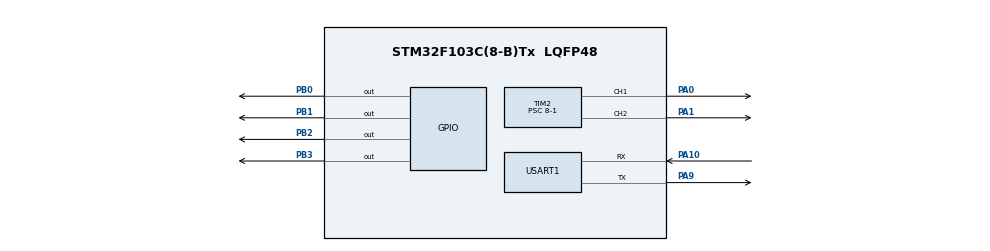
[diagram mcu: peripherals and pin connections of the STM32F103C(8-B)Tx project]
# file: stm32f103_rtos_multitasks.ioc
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FREERTOS.Tasks01=motor01,24,128,StartMotor01,Default,NULL,Dynamic,NULL,NULL;motor02,8,128,StartMotor02,Default,NULL,Dynamic,NULL,NULL
FREERTOS.configUSE_NEWLIB_REENTRANT=1
Mcu.Family=STM32F1
Mcu.Name=STM32F103C(8-B)Tx
Mcu.Package=LQFP48
NVIC.PriorityGroup=NVIC_PRIORITYGROUP_4
NVIC.TIM1_UP_IRQn=true\:15\:0\:false\:false\:true\:false\:false\:true\:true
NVIC.TimeBase=TIM1_UP_IRQn
NVIC.TimeBaseIP=TIM1
PA0-WKUP.Signal=S_TIM2_CH1_ETR
PA1.Signal=S_TIM2_CH2
PA10.Mode=Asynchronous
PA10.Signal=USART1_RX
PA13.Mode=Serial_Wire
PA13.Signal=SYS_JTMS-SWDIO
PA14.Mode=Serial_Wire
PA14.Signal=SYS_JTCK-SWCLK
PA9.Mode=Asynchronous
PA9.Signal=USART1_TX
PB0.Signal=GPIO_Output
PB1.Signal=GPIO_Output
PB2.Signal=GPIO_Output
PB3.Signal=GPIO_Output
ProjectManager.HeapSize=0x200
ProjectManager.StackSize=0x400
ProjectManager.TargetToolchain=STM32CubeIDE
RCC.APB1Freq_Value=8000000
RCC.APB2Freq_Value=8000000
SH.S_TIM2_CH1_ETR.0=TIM2_CH1,PWM Generation1 CH1
SH.S_TIM2_CH2.0=TIM2_CH2,PWM Generation2 CH2
TIM2.Channel-PWM\ Generation1\ CH1=TIM_CHANNEL_1
TIM2.Channel-PWM\ Generation2\ CH2=TIM_CHANNEL_2
TIM2.Period=1000-1
TIM2.Prescaler=8-1
USART1.VirtualMode=VM_ASYNC
VP_FREERTOS_VS_CMSIS_V2.Mode=CMSIS_V2
VP_SYS_VS_tim1.Mode=TIM1
board=custom

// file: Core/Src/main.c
/* USER CODE BEGIN Header */
/**
  ******************************************************************************
  * @file           : main.c
  * @brief          : Main program body
  ******************************************************************************
  * @attention
  *
  * Copyright (c) 2023 STMicroelectronics.
  * All rights reserved.
  *
  * This software is licensed under terms that can be found in the LICENSE file
  * in the root directory of this software component.
  * If no LICENSE file comes with this software, it is provided AS-IS.
  *
  ******************************************************************************
  */
/* USER CODE END Header */
#include "main.h"
#include "cmsis_os.h"

TIM_HandleTypeDef htim2;

UART_HandleTypeDef huart1;

/* Definitions for motor01 */
osThreadId_t motor01Handle;
const osThreadAttr_t motor01_attributes = {
  .name = "motor01",
  .stack_size = 128 * 4,
  .priority = (osPriority_t) osPriorityNormal,
};
/* Definitions for motor02 */
osThreadId_t motor02Handle;
const osThreadAttr_t motor02_attributes = {
  .name = "motor02",
  .stack_size = 128 * 4,
  .priority = (osPriority_t) osPriorityNormal,
};

void SystemClock_Config(void);
static void MX_GPIO_Init(void);
static void MX_USART1_UART_Init(void);
static void MX_TIM2_Init(void);
void StartMotor01(void *argument);
void StartMotor02(void *argument);

int main(void)
{

  /* MCU Configuration--------------------------------------------------------*/

  /* Reset of all peripherals, Initializes the Flash interface and the Systick. */
  HAL_Init();

  /* Configure the system clock */
  SystemClock_Config();

  /* Initialize all configured peripherals */
  MX_GPIO_Init();
  MX_USART1_UART_Init();
  MX_TIM2_Init();
  /* USER CODE BEGIN 2 */
  // Create the semaphore

  /* USER CODE END 2 */

  /* Init scheduler */
  osKernelInitialize();

  /* Create the thread(s) */
  /* creation of motor01 */
  motor01Handle = osThreadNew(StartMotor01, NULL, &motor01_attributes);

  /* creation of motor02 */
  motor02Handle = osThreadNew(StartMotor02, NULL, &motor02_attributes);

  /* Start scheduler */
  osKernelStart();

  /* We should never get here as control is now taken by the scheduler */
  /* Infinite loop */
  while (1)
  {

  }
}

void SystemClock_Config(void)
{
  RCC_OscInitTypeDef RCC_OscInitStruct = {0};
  RCC_ClkInitTypeDef RCC_ClkInitStruct = {0};

  /** Initializes the RCC Oscillators according to the specified parameters
  * in the RCC_OscInitTypeDef structure.
  */
  RCC_OscInitStruct.OscillatorType = RCC_OSCILLATORTYPE_HSI;
  RCC_OscInitStruct.HSIState = RCC_HSI_ON;
  RCC_OscInitStruct.HSICalibrationValue = RCC_HSICALIBRATION_DEFAULT;
  RCC_OscInitStruct.PLL.PLLState = RCC_PLL_NONE;
  if (HAL_RCC_OscConfig(&RCC_OscInitStruct) != HAL_OK)
  {
    Error_Handler();
  }

  /** Initializes the CPU, AHB and APB buses clocks
  */
  RCC_ClkInitStruct.ClockType = RCC_CLOCKTYPE_HCLK|RCC_CLOCKTYPE_SYSCLK
                              |RCC_CLOCKTYPE_PCLK1|RCC_CLOCKTYPE_PCLK2;
  RCC_ClkInitStruct.SYSCLKSource = RCC_SYSCLKSOURCE_HSI;
  RCC_ClkInitStruct.AHBCLKDivider = RCC_SYSCLK_DIV1;
  RCC_ClkInitStruct.APB1CLKDivider = RCC_HCLK_DIV1;
  RCC_ClkInitStruct.APB2CLKDivider = RCC_HCLK_DIV1;

  if (HAL_RCC_ClockConfig(&RCC_ClkInitStruct, FLASH_LATENCY_0) != HAL_OK)
  {
    Error_Handler();
  }
}

static void MX_TIM2_Init(void)
{

  TIM_MasterConfigTypeDef sMasterConfig = {0};
  TIM_OC_InitTypeDef sConfigOC = {0};

  htim2.Instance = TIM2;
  htim2.Init.Prescaler = 8-1;
  htim2.Init.CounterMode = TIM_COUNTERMODE_UP;
  htim2.Init.Period = 1000-1;
  htim2.Init.ClockDivision = TIM_CLOCKDIVISION_DIV1;
  htim2.Init.AutoReloadPreload = TIM_AUTORELOAD_PRELOAD_DISABLE;
  if (HAL_TIM_PWM_Init(&htim2) != HAL_OK)
  {
    Error_Handler();
  }
  sMasterConfig.MasterOutputTrigger = TIM_TRGO_RESET;
  sMasterConfig.MasterSlaveMode = TIM_MASTERSLAVEMODE_DISABLE;
  if (HAL_TIMEx_MasterConfigSynchronization(&htim2, &sMasterConfig) != HAL_OK)
  {
    Error_Handler();
  }
  sConfigOC.OCMode = TIM_OCMODE_PWM1;
  sConfigOC.Pulse = 0;
  sConfigOC.OCPolarity = TIM_OCPOLARITY_HIGH;
  sConfigOC.OCFastMode = TIM_OCFAST_DISABLE;
  if (HAL_TIM_PWM_ConfigChannel(&htim2, &sConfigOC, TIM_CHANNEL_1) != HAL_OK)
  {
    Error_Handler();
  }
  if (HAL_TIM_PWM_ConfigChannel(&htim2, &sConfigOC, TIM_CHANNEL_2) != HAL_OK)
  {
    Error_Handler();
  }
  HAL_TIM_MspPostInit(&htim2);

}

static void MX_USART1_UART_Init(void)
{

  huart1.Instance = USART1;
  huart1.Init.BaudRate = 115200;
  huart1.Init.WordLength = UART_WORDLENGTH_8B;
  huart1.Init.StopBits = UART_STOPBITS_1;
  huart1.Init.Parity = UART_PARITY_NONE;
  huart1.Init.Mode = UART_MODE_TX_RX;
  huart1.Init.HwFlowCtl = UART_HWCONTROL_NONE;
  huart1.Init.OverSampling = UART_OVERSAMPLING_16;
  if (HAL_UART_Init(&huart1) != HAL_OK)
  {
    Error_Handler();
  }

}

static void MX_GPIO_Init(void)
{
  GPIO_InitTypeDef GPIO_InitStruct = {0};

  /* GPIO Ports Clock Enable */
  __HAL_RCC_GPIOA_CLK_ENABLE();
  __HAL_RCC_GPIOB_CLK_ENABLE();

  /*Configure GPIO pin Output Level */
  HAL_GPIO_WritePin(GPIOB, GPIO_PIN_0|GPIO_PIN_1|GPIO_PIN_2|GPIO_PIN_3, GPIO_PIN_RESET);

  /*Configure GPIO pins : PB0 PB1 PB2 PB3 */
  GPIO_InitStruct.Pin = GPIO_PIN_0|GPIO_PIN_1|GPIO_PIN_2|GPIO_PIN_3;
  GPIO_InitStruct.Mode = GPIO_MODE_OUTPUT_PP;
  GPIO_InitStruct.Pull = GPIO_NOPULL;
  GPIO_InitStruct.Speed = GPIO_SPEED_FREQ_LOW;
  HAL_GPIO_Init(GPIOB, &GPIO_InitStruct);

}

void StartMotor01(void *argument)
{
  /* USER CODE BEGIN 5 */
  /* Infinite loop */
  for(;;)
  {

	HAL_GPIO_WritePin(GPIOB, GPIO_PIN_0, GPIO_PIN_SET);
	HAL_GPIO_WritePin(GPIOB, GPIO_PIN_1, GPIO_PIN_RESET);
	// Update the PWM value in the CCR register
	TIM2->CCR1 = 400;
	HAL_TIM_PWM_Start(&htim2, TIM_CHANNEL_1);
    osDelay(1);
  }
  /* USER CODE END 5 */
}

void StartMotor02(void *argument)
{
  /* USER CODE BEGIN StartMotor02 */
  /* Infinite loop */
  for(;;)
  {
	HAL_GPIO_WritePin(GPIOB, GPIO_PIN_2, GPIO_PIN_SET);
	HAL_GPIO_WritePin(GPIOB, GPIO_PIN_3, GPIO_PIN_RESET);
	TIM2 ->CCR2 = 700;
	HAL_TIM_PWM_Start(&htim2, TIM_CHANNEL_2);
    osDelay(1);
  }
  /* USER CODE END StartMotor02 */
}

void HAL_TIM_PeriodElapsedCallback(TIM_HandleTypeDef *htim)
{
  if (htim->Instance == TIM1) {
    HAL_IncTick();
  }
}

void Error_Handler(void)
{
  __disable_irq();
  while (1)
  {
  }
}
